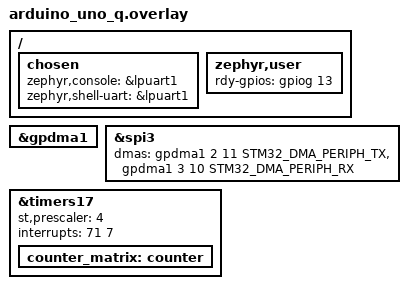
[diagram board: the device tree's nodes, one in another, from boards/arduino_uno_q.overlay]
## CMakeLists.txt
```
# SPDX-License-Identifier: GPL-2.0-or-later
# Copyright (C) 2026 andrewsharmon
cmake_minimum_required(VERSION 3.20.0)
find_package(Zephyr REQUIRED HINTS $ENV{ZEPHYR_BASE})
project(qstep_fw)

# Record neutral paths (no local directory/user names) in the binaries.
zephyr_compile_options(
  -ffile-prefix-map=${ZEPHYR_BASE}/=zephyr/
  -ffile-prefix-map=${ZEPHYR_BASE}/../=
  -ffile-prefix-map=${CMAKE_CURRENT_SOURCE_DIR}/../=firmware/
  -ffile-prefix-map=${CMAKE_BINARY_DIR}/=build/
  -ffile-prefix-map=$ENV{HOME}/=
)

target_include_directories(app PRIVATE ../common)
target_sources(app PRIVATE src/main.c src/stepgen.c src/matrix.c)
```

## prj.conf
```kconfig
# SPDX-License-Identifier: GPL-2.0-or-later
# Copyright (C) 2026 andrewsharmon
CONFIG_GPIO=y
CONFIG_SPI=y
CONFIG_SPI_SLAVE=y
CONFIG_SPI_STM32_DMA=y
CONFIG_DMA=y
CONFIG_COUNTER=y
CONFIG_PRINTK=y
CONFIG_CONSOLE=y
CONFIG_UART_CONSOLE=y
CONFIG_ASSERT=n
CONFIG_CORTEX_M_DWT=y
```

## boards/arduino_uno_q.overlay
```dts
/*
 * SPDX-License-Identifier: GPL-2.0-or-later
 * Copyright (C) 2026 andrewsharmon
 */
/*
 * QStep firmware for the UNO Q STM32U585 (CNC Shield v3 pinout).
 * SPI3 (internal link to the QRB2210 spi5 / spidev0.0) runs as a DMA slave.
 * GPDMA1 request lines on the U5: SPI3_RX = 10, SPI3_TX = 11.
 */
#include <zephyr/dt-bindings/dma/stm32_dma.h>

/ {
	chosen {
		/* LPUART1 is wired to the Linux side (/dev/ttyHS1), so our log is
		 * readable from the MPU once arduino-router is stopped. */
		zephyr,console = &lpuart1;
		zephyr,shell-uart = &lpuart1;
	};

	zephyr,user {
		rdy-gpios = <&gpiog 13 GPIO_ACTIVE_HIGH>; /* "Internal SPI RDY" */
	};
};

&gpdma1 {
	status = "okay";
};

&spi3 {
	status = "okay";
	dmas = <&gpdma1 2 11 STM32_DMA_PERIPH_TX>,
	       <&gpdma1 3 10 STM32_DMA_PERIPH_RX>;
	dma-names = "tx", "rx";
};

/* TIM17 scans the charlieplexed LED matrix at the lowest IRQ priority so it
 * can never delay the SPI link (or, later, step generation). */
&timers17 {
	status = "okay";
	st,prescaler = <4>;
	interrupts = <71 7>;

	counter_matrix: counter {
		status = "okay";
	};
};
```

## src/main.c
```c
/*
 * SPDX-License-Identifier: GPL-2.0-or-later
 * Copyright (C) 2026 andrewsharmon
 */
/*
 * QStep firmware for the UNO Q STM32U585.
 *
 * SPI3 (DMA slave) exchanges one qstep_cmd/qstep_stat pair per LinuxCNC servo
 * period (see ../common/qstep_proto.h). Commands feed the DDS stepgen in
 * stepgen.c; the status frame for the next transfer is prepared as soon as a
 * command has been applied.
 *
 * Safety: if no valid command arrives for WATCHDOG_MS while enabled, stepping
 * stops and the drivers are disabled. The trip latches until the host sends a
 * command without QSTEP_CMD_ENABLE (i.e. LinuxCNC goes through machine-off).
 */

#include <zephyr/kernel.h>
#include <zephyr/device.h>
#include <zephyr/drivers/gpio.h>
#include <zephyr/drivers/spi.h>
#include <zephyr/sys/printk.h>
#include <string.h>

#include "qstep_proto.h"
#include "matrix.h"
#include "stepgen.h"

#define WATCHDOG_MS 20

static const struct device *const spi = DEVICE_DT_GET(DT_NODELABEL(spi3));
static const struct gpio_dt_spec rdy = GPIO_DT_SPEC_GET(DT_PATH(zephyr_user), rdy_gpios);

static const struct spi_config spi_cfg = {
	.operation = SPI_OP_MODE_SLAVE | SPI_WORD_SET(8) | SPI_TRANSFER_MSB,
	/* The master drives SCLK; the driver still validates this, so not 0. */
	.frequency = 80000000,
};

static union {
	struct qstep_cmd cmd;
	uint8_t raw[QSTEP_FRAME_LEN];
} rx __aligned(32);

static union {
	struct qstep_stat stat;
	uint8_t raw[QSTEP_FRAME_LEN];
} tx __aligned(32);

static volatile uint32_t frames_ok, frames_bad;
static volatile int64_t last_frame_ms;
static volatile bool wd_tripped, crc_seen;
static uint8_t last_seq;

static void watchdog_fn(struct k_timer *t)
{
	if (stepgen_enabled() && k_uptime_get() - last_frame_ms > WATCHDOG_MS) {
		stepgen_enable(false);
		io_set_outputs(0);
		wd_tripped = true;
	}
}

K_TIMER_DEFINE(watchdog, watchdog_fn, NULL);

static void prepare_status(void)
{
	struct qstep_stat *s = &tx.stat;

	memset(s, 0, sizeof(*s));
	s->magic = QSTEP_STAT_MAGIC;
	s->seq_echo = last_seq;
	s->status = (stepgen_enabled() ? QSTEP_ST_ENABLED : 0) | (wd_tripped ? QSTEP_ST_WATCHDOG : 0) |
		    (crc_seen ? QSTEP_ST_CRC_SEEN : 0);
	int32_t steps[QSTEP_JOINTS];
	uint16_t imax, iavg;

	stepgen_get_pos(steps);
	memcpy(s->steps, steps, sizeof(steps));
	s->inputs = io_get_inputs();
	s->frames_ok = frames_ok;
	s->frames_bad = frames_bad;
	stepgen_isr_stats(&imax, &iavg);
	s->isr_max_cycles = imax;
	s->isr_avg_cycles = iavg;
	s->proto_version = QSTEP_PROTO_VERSION;
	s->crc = qstep_crc16(s, QSTEP_FRAME_LEN - 2);
}

static void apply_command(const struct qstep_cmd *c)
{
	bool want = c->flags & QSTEP_CMD_ENABLE;

	last_seq = c->seq;
	last_frame_ms = k_uptime_get();

	if (wd_tripped) {
		if (want) {
			return; /* stay off until the host acknowledges with enable=0 */
		}
		wd_tripped = false;
	}
	if (want != stepgen_enabled()) {
		stepgen_enable(want);
	}
	int32_t incr[QSTEP_JOINTS];

	memcpy(incr, c->dds_incr, sizeof(incr));
	stepgen_set_incr(incr);
	io_set_outputs(want ? c->outputs : 0);
}

/* Once a second on LPUART1 (/dev/ttyHS1); lowest priority so it never delays SPI. */
static void report_thread(void *a, void *b, void *c)
{
	for (;;) {
		k_msleep(1000);
		uint16_t imax, iavg;
		int32_t p[QSTEP_JOINTS];

		stepgen_isr_stats(&imax, &iavg);
		stepgen_get_pos(p);
		printk("ok=%u bad=%u en=%d wd=%d pos=%d,%d,%d isr avg/max=%u/%u cyc in=%02x\n",
		       frames_ok, frames_bad, stepgen_enabled(), wd_tripped, p[0], p[1], p[2], iavg,
		       imax, io_get_inputs());
	}
}

K_THREAD_DEFINE(report, 1024, report_thread, NULL, NULL, NULL, K_LOWEST_APPLICATION_THREAD_PRIO,
		0, 0);

int main(void)
{
	printk("\nqstep-fw proto %d, %d joints, base %u Hz\n", QSTEP_PROTO_VERSION, QSTEP_JOINTS,
	       QSTEP_BASE_FREQ_HZ);

	if (stepgen_init() != 0) {
		printk("stepgen init failed\n");
		return 0;
	}
	if (matrix_start() != 0) {
		printk("matrix: failed to start\n");
	}
	if (!device_is_ready(spi) || !gpio_is_ready_dt(&rdy)) {
		printk("spi3/rdy not ready\n");
		return 0;
	}
	gpio_pin_configure_dt(&rdy, GPIO_OUTPUT_INACTIVE);
	k_timer_start(&watchdog, K_MSEC(5), K_MSEC(5));

	prepare_status();

	struct spi_buf txb = {.buf = tx.raw, .len = QSTEP_FRAME_LEN};
	struct spi_buf rxb = {.buf = rx.raw, .len = QSTEP_FRAME_LEN};
	struct spi_buf_set txs = {.buffers = &txb, .count = 1};
	struct spi_buf_set rxs = {.buffers = &rxb, .count = 1};

	for (;;) {
		gpio_pin_set_dt(&rdy, 1);
		int ret = spi_transceive(spi, &spi_cfg, &txs, &rxs);

		gpio_pin_set_dt(&rdy, 0);

		if (ret == QSTEP_FRAME_LEN && rx.cmd.magic == QSTEP_CMD_MAGIC &&
		    rx.cmd.crc == qstep_crc16(rx.raw, QSTEP_FRAME_LEN - 2)) {
			frames_ok++;
			apply_command(&rx.cmd);
		} else {
			frames_bad++;
			crc_seen = true;
		}
		prepare_status();
	}
	return 0;
}
```

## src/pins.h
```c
/*
 * SPDX-License-Identifier: GPL-2.0-or-later
 * Copyright (C) 2026 andrewsharmon
 */
/*
 * Pin map: Arduino CNC Shield v3 (GRBL 1.1 layout) on the UNO Q header.
 * Everything that needs to change to move signals (e.g. to JMISC) is here.
 */
#pragma once

#include <stm32u5xx.h>

struct pin {
	GPIO_TypeDef *port;
	uint8_t bit;
};

#define PIN_NONE {NULL, 0}

/* Joints 0..3 = X, Y, Z, A.  A has no dedicated pins on the shield. */
#define STEP_PINS {{GPIOB, 3} /* D2 */, {GPIOB, 0} /* D3 */, {GPIOA, 12} /* D4 */, PIN_NONE}
#define DIR_PINS  {{GPIOA, 11} /* D5 */, {GPIOB, 1} /* D6 */, {GPIOB, 2} /* D7 */, PIN_NONE}

/* Shared driver enable, active low (DRV8825 /ENABLE). */
#define ENABLE_PIN {GPIOB, 4} /* D8 */

/* Inputs, active low with internal pull-up; order matches QSTEP_IN_* bits. */
#define INPUT_PINS {                                                                   \
	{GPIOB, 8},  /* D9  X limit */                                                  \
	{GPIOB, 9},  /* D10 Y limit */                                                  \
	{GPIOB, 15}, /* D11 Z limit */                                                  \
	{GPIOA, 4},  /* A0  abort */                                                    \
	{GPIOA, 5},  /* A1  feed hold */                                                \
	{GPIOA, 6},  /* A2  cycle start/resume */                                       \
	{GPIOC, 0},  /* A5  probe */                                                    \
}

/* Outputs; order matches QSTEP_OUT_* bits. */
#define OUTPUT_PINS {                                                                  \
	{GPIOB, 14}, /* D12 spindle enable */                                           \
	{GPIOB, 13}, /* D13 spindle direction */                                        \
	{GPIOA, 7},  /* A3  coolant */                                                  \
}
```

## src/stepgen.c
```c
/*
 * SPDX-License-Identifier: GPL-2.0-or-later
 * Copyright (C) 2026 andrewsharmon
 */
/*
 * DDS step generation for up to QSTEP_JOINTS joints.
 *
 * TIM6 interrupts at QSTEP_BASE_FREQ_HZ (100 kHz). Each tick:
 *   1. lower the STEP pins raised on the previous tick (10 us pulses),
 *   2. per joint, add |incr| to a 32-bit accumulator; an overflow is one step.
 * |incr| is clamped to 2^31, so a joint steps at most every other tick
 * (50 kHz max, 10 us high / >= 10 us low, well inside the DRV8825 limits).
 * A direction change holds stepping for DIR_HOLD_TICKS (20 us setup time;
 * the DRV8825 needs 650 ns).
 *
 * The ISR is a Zephyr "direct" ISR at the highest priority. It never calls
 * the kernel and touches the GPIO registers directly.
 */

#include <zephyr/kernel.h>
#include <zephyr/device.h>
#include <zephyr/drivers/gpio.h>
#include <zephyr/irq.h>
#include <stm32u5xx.h>
#include <stm32u5xx_ll_bus.h>

#include "pins.h"
#include "stepgen.h"

#define DIR_HOLD_TICKS 2
#define INCR_MAX       0x80000000u

static const struct pin step_pins[QSTEP_JOINTS] = STEP_PINS;
static const struct pin dir_pins[QSTEP_JOINTS] = DIR_PINS;
static const struct pin enable_pin = ENABLE_PIN;
static const struct pin input_pins[] = INPUT_PINS;
static const struct pin output_pins[] = OUTPUT_PINS;

static volatile int32_t incr[QSTEP_JOINTS];
static volatile int32_t pos[QSTEP_JOINTS];
static volatile bool enabled;

static uint32_t acc[QSTEP_JOINTS];
static int8_t cur_dir[QSTEP_JOINTS] = {1, 1, 1, 1};
static uint8_t hold[QSTEP_JOINTS];
static bool pending[QSTEP_JOINTS];

/* STEP pins raised on the last tick, per port, so the next tick can lower them. */
static uint32_t raised_a, raised_b, raised_c;

static volatile uint32_t isr_max, isr_sum, isr_count;
static volatile uint16_t isr_avg;

static inline void pin_write(const struct pin *p, bool high)
{
	if (p->port) {
		p->port->BSRR = high ? (1U << p->bit) : (1U << (p->bit + 16));
	}
}

static inline uint32_t *raised_for(GPIO_TypeDef *port)
{
	return port == GPIOA ? &raised_a : port == GPIOB ? &raised_b : &raised_c;
}

ISR_DIRECT_DECLARE(stepgen_isr)
{
	uint32_t t0 = DWT->CYCCNT;

	TIM6->SR = 0;

	/* End the pulses started on the previous tick. */
	GPIOA->BSRR = raised_a << 16;
	GPIOB->BSRR = raised_b << 16;
	GPIOC->BSRR = raised_c << 16;
	raised_a = raised_b = raised_c = 0;

	if (enabled) {
		for (int j = 0; j < QSTEP_JOINTS; j++) {
			if (!step_pins[j].port) {
				continue;
			}
			int32_t inc = incr[j];
			uint32_t mag = inc < 0 ? (uint32_t)(-(int64_t)inc) : (uint32_t)inc;
			int8_t dir = inc < 0 ? -1 : (inc > 0 ? 1 : cur_dir[j]);

			if (mag > INCR_MAX) {
				mag = INCR_MAX;
			}
			if (dir != cur_dir[j]) {
				cur_dir[j] = dir;
				pin_write(&dir_pins[j], dir > 0);
				hold[j] = DIR_HOLD_TICKS;
			}

			uint32_t old = acc[j];

			acc[j] = old + mag;
			if (acc[j] < old) {
				pending[j] = true;
			}
			if (hold[j]) {
				hold[j]--;
			} else if (pending[j]) {
				pending[j] = false;
				*raised_for(step_pins[j].port) |= 1U << step_pins[j].bit;
				pos[j] += cur_dir[j];
			}
		}
		GPIOA->BSRR = raised_a;
		GPIOB->BSRR = raised_b;
		GPIOC->BSRR = raised_c;
	}

	uint32_t dt = DWT->CYCCNT - t0;

	if (dt > isr_max) {
		isr_max = dt;
	}
	isr_sum += dt;
	if (++isr_count == 65536) {
		isr_avg = isr_sum >> 16;
		isr_sum = 0;
		isr_count = 0;
	}
	return 0; /* no reschedule needed */
}

static const struct device *port_dev(GPIO_TypeDef *port)
{
	if (port == GPIOA) {
		return DEVICE_DT_GET(DT_NODELABEL(gpioa));
	}
	if (port == GPIOB) {
		return DEVICE_DT_GET(DT_NODELABEL(gpiob));
	}
	return DEVICE_DT_GET(DT_NODELABEL(gpioc));
}

static int pin_setup(const struct pin *p, gpio_flags_t flags)
{
	if (!p->port) {
		return 0;
	}
	const struct device *dev = port_dev(p->port);

	/* Readying the port device also turns on its clock. */
	if (!device_is_ready(dev)) {
		return -ENODEV;
	}
	return gpio_pin_configure(dev, p->bit, flags);
}

int stepgen_init(void)
{
	int err = 0;

	/* Drivers disabled (EN high) before anything else. */
	err |= pin_setup(&enable_pin, GPIO_OUTPUT_HIGH);
	for (int j = 0; j < QSTEP_JOINTS; j++) {
		err |= pin_setup(&step_pins[j], GPIO_OUTPUT_LOW);
		err |= pin_setup(&dir_pins[j], GPIO_OUTPUT_HIGH);
	}
	for (size_t i = 0; i < ARRAY_SIZE(input_pins); i++) {
		err |= pin_setup(&input_pins[i], GPIO_INPUT | GPIO_PULL_UP);
	}
	for (size_t i = 0; i < ARRAY_SIZE(output_pins); i++) {
		err |= pin_setup(&output_pins[i], GPIO_OUTPUT_LOW);
	}
	if (err) {
		return -EIO;
	}

	/* Cycle counter for ISR timing. */
	CoreDebug->DEMCR |= CoreDebug_DEMCR_TRCENA_Msk;
	DWT->CYCCNT = 0;
	DWT->CTRL |= DWT_CTRL_CYCCNTENA_Msk;

	/* TIM6: basic timer on APB1 (timer clock = SystemCoreClock here). */
	LL_APB1_GRP1_EnableClock(LL_APB1_GRP1_PERIPH_TIM6);
	TIM6->CR1 = 0;
	TIM6->PSC = 0;
	TIM6->ARR = (SystemCoreClock / QSTEP_BASE_FREQ_HZ) - 1;
	TIM6->EGR = TIM_EGR_UG;
	TIM6->SR = 0;
	TIM6->DIER = TIM_DIER_UIE;

	IRQ_DIRECT_CONNECT(TIM6_IRQn, 0, stepgen_isr, 0);
	irq_enable(TIM6_IRQn);
	TIM6->CR1 = TIM_CR1_CEN;
	return 0;
}

void stepgen_set_incr(const int32_t in[QSTEP_JOINTS])
{
	for (int j = 0; j < QSTEP_JOINTS; j++) {
		incr[j] = enabled ? in[j] : 0;
	}
}

void stepgen_enable(bool on)
{
	if (!on) {
		for (int j = 0; j < QSTEP_JOINTS; j++) {
			incr[j] = 0;
		}
	}
	enabled = on;
	pin_write(&enable_pin, !on); /* active low */
}

bool stepgen_enabled(void)
{
	return enabled;
}

void stepgen_get_pos(int32_t out[QSTEP_JOINTS])
{
	for (int j = 0; j < QSTEP_JOINTS; j++) {
		out[j] = pos[j];
	}
}

void stepgen_isr_stats(uint16_t *max_cycles, uint16_t *avg_cycles)
{
	*max_cycles = isr_max > 0xFFFF ? 0xFFFF : isr_max;
	*avg_cycles = isr_avg;
}

void io_set_outputs(uint32_t outputs)
{
	for (size_t i = 0; i < ARRAY_SIZE(output_pins); i++) {
		pin_write(&output_pins[i], outputs & (1U << i));
	}
}

uint32_t io_get_inputs(void)
{
	uint32_t in = 0;

	for (size_t i = 0; i < ARRAY_SIZE(input_pins); i++) {
		if (!(input_pins[i].port->IDR & (1U << input_pins[i].bit))) {
			in |= 1U << i;
		}
	}
	return in;
}
```

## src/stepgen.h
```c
/*
 * SPDX-License-Identifier: GPL-2.0-or-later
 * Copyright (C) 2026 andrewsharmon
 */
#pragma once

#include <stdbool.h>
#include <stdint.h>

#include "qstep_proto.h"

/* Configure step/dir/enable/IO pins and start the TIM6 stepgen tick. */
int stepgen_init(void);

/* Set the per-tick DDS increments (signed, sign = direction). */
void stepgen_set_incr(const int32_t incr[QSTEP_JOINTS]);

/* Enable or disable the drivers. Disabling also zeroes all increments. */
void stepgen_enable(bool on);
bool stepgen_enabled(void);

/* Absolute step counts per joint. */
void stepgen_get_pos(int32_t pos[QSTEP_JOINTS]);

/* Stepgen ISR cost in CPU cycles (worst since boot, running average). */
void stepgen_isr_stats(uint16_t *max_cycles, uint16_t *avg_cycles);

void io_set_outputs(uint32_t outputs);
uint32_t io_get_inputs(void);
```
